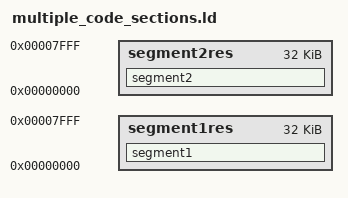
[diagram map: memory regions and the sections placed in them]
/* DO NOT EDIT!
   This file was automatically generated by m68k-palmos-multigen v2.3
   from ../Sections.def  */

MEMORY
{
	segment1res : ORIGIN = 0x0, LENGTH = 32768
	segment2res : ORIGIN = 0x0, LENGTH = 32768
}

SECTIONS
{
	segment1 : { *(segment1) } > segment1res
	segment2 : { *(segment2) } > segment2res
}
